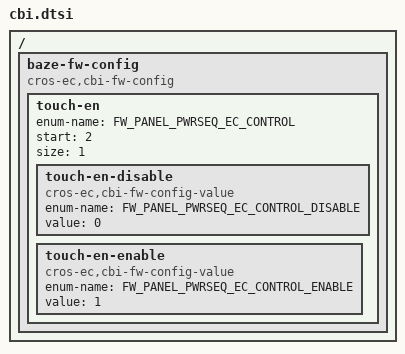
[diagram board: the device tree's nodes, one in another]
/* Copyright 2025 The ChromiumOS Authors
 * Use of this source code is governed by a BSD-style license that can be
 * found in the LICENSE file.
 */

/ {
	baze-fw-config {
		compatible = "cros-ec,cbi-fw-config";

		/*
		 * FW_CONFIG field to enable touch panel power sequence
		 * control or not.
		 */
		touch-en {
			enum-name = "FW_PANEL_PWRSEQ_EC_CONTROL";
			start = <2>;
			size = <1>;

			touch-en-disable {
				compatible = "cros-ec,cbi-fw-config-value";
				enum-name = "FW_PANEL_PWRSEQ_EC_CONTROL_DISABLE";
				value = <0>;
			};
			touch-en-enable {
				compatible = "cros-ec,cbi-fw-config-value";
				enum-name = "FW_PANEL_PWRSEQ_EC_CONTROL_ENABLE";
				value = <1>;
			};
		};
	};
};
